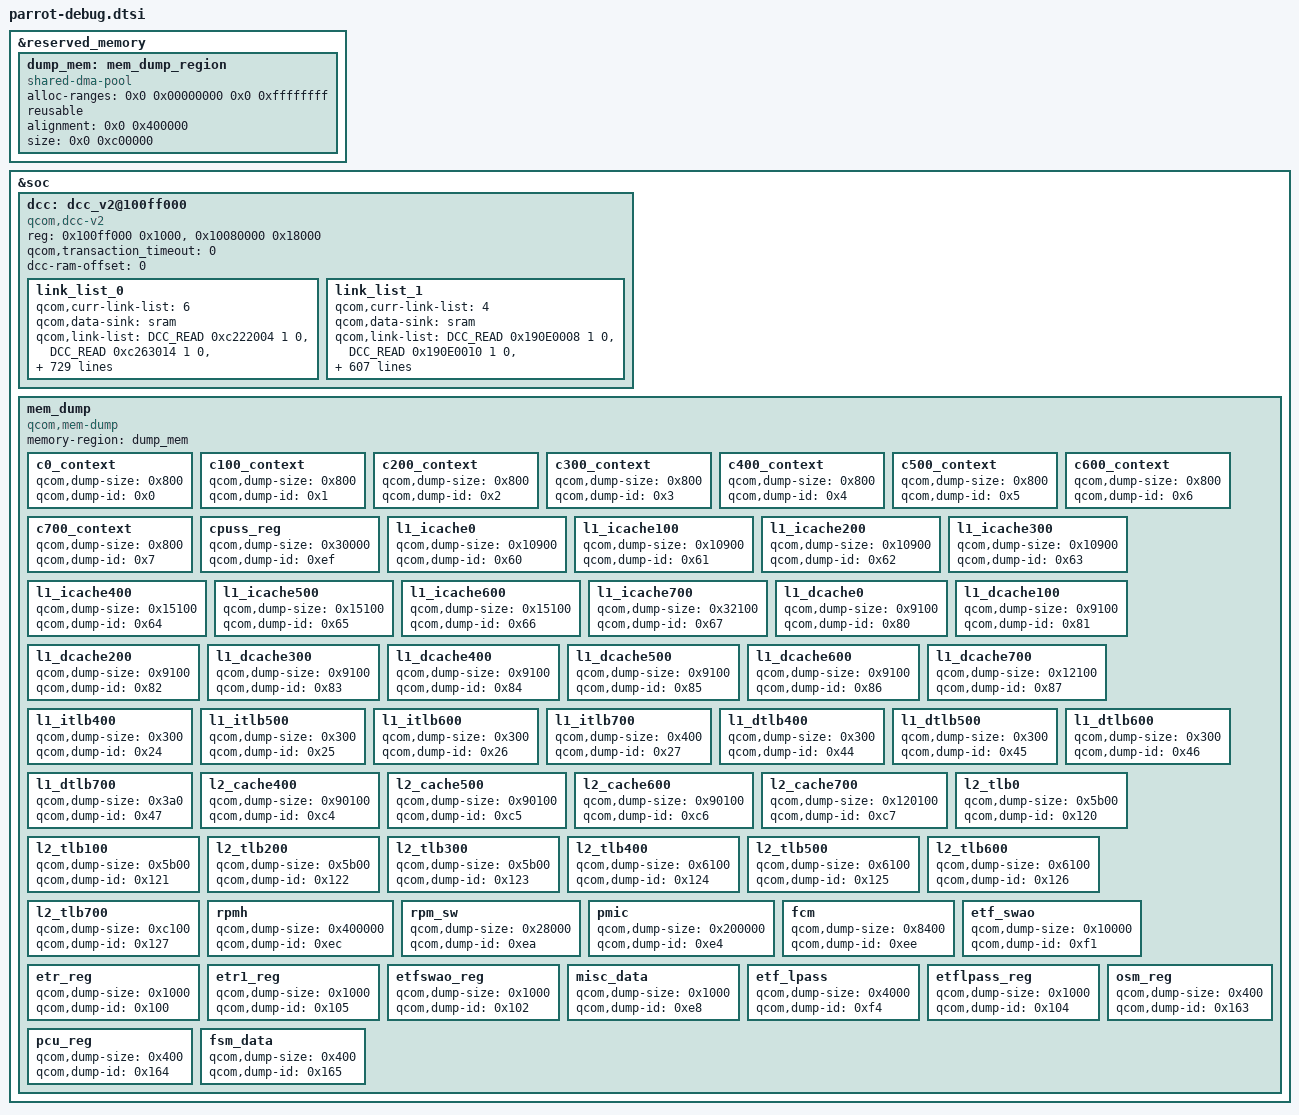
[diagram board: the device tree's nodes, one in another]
#include <dt-bindings/soc/qcom,dcc_v2.h>

&reserved_memory {
	#address-cells = <2>;
	#size-cells = <2>;
	ranges;

	dump_mem: mem_dump_region {
		compatible = "shared-dma-pool";
		alloc-ranges = <0x0 0x00000000 0x0 0xffffffff>;
		reusable;
		alignment = <0x0 0x400000>;
		size = <0x0 0xc00000>;
	};
};

&soc {
	dcc: dcc_v2@100ff000 {
		compatible = "qcom,dcc-v2";
		reg = <0x100ff000 0x1000>,
		      <0x10080000 0x18000>;

		qcom,transaction_timeout = <0>;

		reg-names = "dcc-base", "dcc-ram-base";
		dcc-ram-offset = <0>;

		link_list_0 {
			qcom,curr-link-list = <6>;
			qcom,data-sink = "sram";
			qcom,link-list = <DCC_READ 0xc222004 1 0>,
				<DCC_READ 0xc263014 1 0>,
				<DCC_READ 0xc2630e0 1 0>,
				<DCC_READ 0xc2630ec 1 0>,
				<DCC_READ 0xc2630a0 16 0>,
				<DCC_READ 0xc2630e8 1 0>,
				<DCC_READ 0xc26313c 1 0>,
				<DCC_READ 0xc223004 1 0>,
				<DCC_READ 0xc265014 1 0>,
				<DCC_READ 0xc2650e0 1 0>,
				<DCC_READ 0xc2650ec 1 0>,
				<DCC_READ 0xc2650a0 16 0>,
				<DCC_READ 0xc2650e8 1 0>,
				<DCC_READ 0xc26513c 1 0>,
				<DCC_READ 0x1780005c 1 0>,
				<DCC_READ 0x1781005c 1 0>,
				<DCC_READ 0x1782005c 1 0>,
				<DCC_READ 0x1783005c 1 0>,
				<DCC_READ 0x1784005c 1 0>,
				<DCC_READ 0x1785005c 1 0>,
				<DCC_READ 0x1786005c 1 0>,
				<DCC_READ 0x1787005c 1 0>,
				<DCC_READ 0x1740003c 1 0>,
				<DCC_READ 0x17600238 1 0>,
				<DCC_READ 0x17600240 11 0>,
				<DCC_READ 0x17600404 1 0>,
				<DCC_READ 0x1760041c 2 0>,
				<DCC_READ 0x17600434 1 0>,
				<DCC_READ 0x1760043c 2 0>,
				<DCC_READ 0x17400438 1 0>,
				<DCC_READ 0x17600044 1 0>,
				<DCC_READ 0x17600500 1 0>,
				<DCC_READ 0x17600504 5 0>,
				<DCC_READ 0x17900908 1 0>,
				<DCC_READ 0x17900c18 1 0>,
				<DCC_READ 0x17901908 1 0>,
				<DCC_READ 0x17901c18 1 0>,
				<DCC_READ 0x17b90810 1 0>,
				<DCC_READ 0x17b90814 1 0>,
				<DCC_READ 0x17b90818 1 0>,
				<DCC_READ 0x17b93a84 1 0>,
				<DCC_READ 0x17ba0810 1 0>,
				<DCC_READ 0x17ba0c50 1 0>,
				<DCC_READ 0x17ba0814 1 0>,
				<DCC_READ 0x17ba0c54 1 0>,
				<DCC_READ 0x17ba0818 1 0>,
				<DCC_READ 0x17ba0c58 1 0>,
				<DCC_READ 0x17ba3a84 2 0>,
				<DCC_READ 0x17b93500 40 0>,
				<DCC_READ 0x17ba3500 40 0>,
				<DCC_READ 0x17a80000 16 0>,
				<DCC_READ 0x17a82000 6 0>,
				<DCC_READ 0x17a84000 16 0>,
				<DCC_READ 0x17a86000 6 0>,
				<DCC_READ 0x17a88000 16 0>,
				<DCC_READ 0x17a8a000 6 0>,
				<DCC_READ 0xc201244 1 0>,
				<DCC_READ 0xc202244 1 0>,
				<DCC_READ 0x17b00000 1 0>,
				<DCC_READ 0x17a94030 1 0>,
				<DCC_READ 0x17a9408c 1 0>,
				<DCC_WRITE 0x17a9409c 0x78 0>,
				<DCC_WRITE 0x17a9409c 0x0 0>,
				<DCC_WRITE 0x17a94048 0x1 0>,
				<DCC_WRITE 0x17a94090 0x0 0>,
				<DCC_WRITE 0x17a94090 0x25 0>,
				<DCC_READ 0x17a94098 1 0>,
				<DCC_WRITE 0x17a94048 0x1D 0>,
				<DCC_WRITE 0x17a94090 0x0 0>,
				<DCC_WRITE 0x17a94090 0x25 0>,
				<DCC_READ 0x17a94098 1 0>,
				<DCC_READ 0x17a90030 1 0>,
				<DCC_READ 0x17a9008c 1 0>,
				<DCC_WRITE 0x17a9009c 0x78 0>,
				<DCC_WRITE 0x17a9009c 0x0 0>,
				<DCC_WRITE 0x17a90048 0x1 0>,
				<DCC_WRITE 0x17a90090 0x0 0>,
				<DCC_WRITE 0x17a90090 0x25 0>,
				<DCC_READ 0x17a90098 1 0>,
				<DCC_WRITE 0x17a90048 0x1D 0>,
				<DCC_WRITE 0x17a90090 0x0 0>,
				<DCC_WRITE 0x17a90090 0x25 0>,
				<DCC_READ 0x17a90098 1 0>,
				<DCC_READ 0x17a92030 1 0>,
				<DCC_READ 0x17a9208c 1 0>,
				<DCC_WRITE 0x17a9209c 0x78 0>,
				<DCC_WRITE 0x17a9209c 0x0 0>,
				<DCC_WRITE 0x17a92048 0x1 0>,
				<DCC_WRITE 0x17a92090 0x0 0>,
				<DCC_WRITE 0x17a92090 0x25 0>,
				<DCC_READ 0x17a92098 1 0>,
				<DCC_WRITE 0x17a92048 0x1D 0>,
				<DCC_WRITE 0x17a92090 0x0 0>,
				<DCC_WRITE 0x17a92090 0x25 0>,
				<DCC_READ 0x17a92098 1 0>,
				<DCC_READ 0x221C20A4 1 0>,
				<DCC_READ 0x221c21c4 1 0>,
				<DCC_READ 0x1fc8000 1 0>,
				<DCC_READ 0x17400038 1 0>,
				<DCC_READ 0x17d91020 1 0>,
				<DCC_READ 0x17d92020 1 0>,
				<DCC_READ 0x17d90020 1 0>,
				<DCC_READ 0x17d9134c 1 0>,
				<DCC_READ 0x17d9234c 1 0>,
				<DCC_READ 0x17d9034c 1 0>,
				<DCC_READ 0x17d91300 1 0>,
				<DCC_READ 0x17d92300 1 0>,
				<DCC_READ 0x17d90300 1 0>,
				<DCC_READ 0x17B784A0 12 0>,
				<DCC_READ 0x17B78520 1 0>,
				<DCC_READ 0x17B78588 1 0>,
				<DCC_READ 0x17B78D90 8 0>,
				<DCC_READ 0x17B79010 6 0>,
				<DCC_READ 0x17B79090 6 0>,
				<DCC_READ 0x17B79A90 4 0>,
				<DCC_READ 0x17B70220 2 0>,
				<DCC_READ 0x17B702A0 2 0>,
				<DCC_READ 0x17B704A0 12 0>,
				<DCC_READ 0x17B70520 1 0>,
				<DCC_READ 0x17B70588 1 0>,
				<DCC_READ 0x17B70D90 12 0>,
				<DCC_READ 0x17B71010 10 0>,
				<DCC_READ 0x17B71090 10 0>,
				<DCC_READ 0x17B71A90 8 0>,
				<DCC_READ 0x19100010 1 0>,
				<DCC_READ 0x19100020 1 0>,
				<DCC_READ 0x19100024 1 0>,
				<DCC_READ 0x19100028 1 0>,
				<DCC_READ 0x1910002C 1 0>,
				<DCC_READ 0x19100030 1 0>,
				<DCC_READ 0x19100034 1 0>,
				<DCC_READ 0x19140010 1 0>,
				<DCC_READ 0x19140020 1 0>,
				<DCC_READ 0x19140024 1 0>,
				<DCC_READ 0x19140028 1 0>,
				<DCC_READ 0x1914002C 1 0>,
				<DCC_READ 0x19140030 1 0>,
				<DCC_READ 0x19140034 1 0>,
				<DCC_READ 0x19180010 1 0>,
				<DCC_READ 0x19180020 1 0>,
				<DCC_READ 0x19180024 1 0>,
				<DCC_READ 0x19180028 1 0>,
				<DCC_READ 0x1918002C 1 0>,
				<DCC_READ 0x19180030 1 0>,
				<DCC_READ 0x19180034 1 0>,
				<DCC_READ 0x19180410 1 0>,
				<DCC_READ 0x19180420 1 0>,
				<DCC_READ 0x19180424 1 0>,
				<DCC_READ 0x19180428 1 0>,
				<DCC_READ 0x1918042C 1 0>,
				<DCC_READ 0x19180430 1 0>,
				<DCC_READ 0x19180434 1 0>,
				<DCC_READ 0x19180848 1 0>,
				<DCC_READ 0x19120008 1 0>,
				<DCC_READ 0x1912000C 1 0>,
				<DCC_READ 0x19160008 1 0>,
				<DCC_READ 0x1916000C 1 0>,
				<DCC_READ 0x191B0008 1 0>,
				<DCC_READ 0x191B000C 1 0>,
				<DCC_READ 0x191B0408 1 0>,
				<DCC_READ 0x191B040C 1 0>,
				<DCC_READ 0x191B1080 1 0>,
				<DCC_READ 0x191B1084 1 0>,
				<DCC_READ 0x191B1088 1 0>,
				<DCC_LOOP 0x9 0 0>,
				<DCC_READ 0x191B1090 2 0>,
				<DCC_LOOP 0x1 0 0>,
				<DCC_READ 0x191B1098 1 0>,
				<DCC_READ 0x19161080 1 0>,
				<DCC_READ 0x19161084 1 0>,
				<DCC_READ 0x19161088 1 0>,
				<DCC_LOOP 0x4 0 0>,
				<DCC_READ 0x19161090 2 0>,
				<DCC_LOOP 0x1 0 0>,
				<DCC_READ 0x19161098 1 0>,
				<DCC_READ 0x19121080 1 0>,
				<DCC_READ 0x19121084 1 0>,
				<DCC_READ 0x19121088 1 0>,
				<DCC_LOOP 0x4 0 0>,
				<DCC_READ 0x19121090 2 0>,
				<DCC_LOOP 0x1 0 0>,
				<DCC_READ 0x19121098 1 0>,
				<DCC_READ 0x191B1000 1 0>,
				<DCC_READ 0x191B1004 1 0>,
				<DCC_READ 0x191B1008 1 0>,
				<DCC_LOOP 0x3 0 0>,
				<DCC_READ 0x191B1010 2 0>,
				<DCC_LOOP 0x1 0 0>,
				<DCC_READ 0x191B1018 1 0>,
				<DCC_READ 0x19121000 1 0>,
				<DCC_READ 0x19121004 1 0>,
				<DCC_READ 0x19121008 1 0>,
				<DCC_LOOP 0x2 0 0>,
				<DCC_READ 0x19121010 2 0>,
				<DCC_LOOP 0x1 0 0>,
				<DCC_READ 0x19121018 1 0>,
				<DCC_READ 0x19161000 1 0>,
				<DCC_READ 0x19161004 1 0>,
				<DCC_READ 0x19161008 1 0>,
				<DCC_LOOP 0x2 0 0>,
				<DCC_READ 0x19161010 2 0>,
				<DCC_LOOP 0x1 0 0>,
				<DCC_READ 0x19161018 1 0>,
				<DCC_READ 0x19130010 1 0>,
				<DCC_READ 0x19131010 1 0>,
				<DCC_READ 0x19132010 1 0>,
				<DCC_READ 0x19170010 1 0>,
				<DCC_READ 0x19171010 1 0>,
				<DCC_READ 0x19172010 1 0>,
				<DCC_READ 0x191B3010 1 0>,
				<DCC_READ 0x191B5010 1 0>,
				<DCC_READ 0x191B6010 1 0>,
				<DCC_READ 0x191B7010 1 0>,
				<DCC_READ 0x191B8010 1 0>,
				<DCC_READ 0x191B9010 1 0>,
				<DCC_READ 0x191BA010 1 0>,
				<DCC_READ 0x191BB010 1 0>,
				<DCC_READ 0x191BC010 1 0>,
				<DCC_READ 0x19120010 1 0>,
				<DCC_LOOP 0x4 0 0>,
				<DCC_READ 0x19120030 3 0>,
				<DCC_LOOP 0x1 0 0>,
				<DCC_READ 0x19120008 2 0>,
				<DCC_LOOP 0xC6 0 0>,
				<DCC_READ 0x19120020 2 0>,
				<DCC_LOOP 0x1 0 0>,
				<DCC_READ 0x19160010 1 0>,
				<DCC_LOOP 0x4 0 0>,
				<DCC_READ 0x19160030 3 0>,
				<DCC_LOOP 0x1 0 0>,
				<DCC_READ 0x19160008 2 0>,
				<DCC_LOOP 0xC6 0 0>,
				<DCC_READ 0x19160020 2 0>,
				<DCC_LOOP 0x1 0 0>,
				<DCC_READ 0x191B0010 1 0>,
				<DCC_LOOP 0x4 0 0>,
				<DCC_READ 0x191B0030 3 0>,
				<DCC_LOOP 0x1 0 0>,
				<DCC_READ 0x191B0008 2 0>,
				<DCC_LOOP 0x6A 0 0>,
				<DCC_READ 0x191B0020 2 0>,
				<DCC_LOOP 0x1 0 0>,
				<DCC_READ 0x191B0410 1 0>,
				<DCC_LOOP 0x4 0 0>,
				<DCC_READ 0x191B0430 3 0>,
				<DCC_LOOP 0x1 0 0>,
				<DCC_READ 0x191B0408 2 0>,
				<DCC_LOOP 0x66 0 0>,
				<DCC_READ 0x191B0420 2 0>,
				<DCC_LOOP 0x1 0 0>,
				<DCC_READ 0x19184100 4 0>,
				<DCC_READ 0x19186100 1 0>,
				<DCC_READ 0x3d0201c 1 0>,
				<DCC_READ 0x3d00000 1 0>,
				<DCC_READ 0x3d00008 1 0>,
				<DCC_READ 0x3d00044 1 0>,
				<DCC_READ 0x3d00058 6 0>,
				<DCC_READ 0x3d0007c 20 0>,
				<DCC_READ 0x3d000e0 5 0>,
				<DCC_READ 0x3d00108 1 0>,
				<DCC_READ 0x3d00110 1 0>,
				<DCC_READ 0x3d0011c 1 0>,
				<DCC_READ 0x3d00124 2 0>,
				<DCC_READ 0x3d00140 1 0>,
				<DCC_READ 0x3d00158 1 0>,
				<DCC_READ 0x3d002b4 2 0>,
				<DCC_READ 0x3d002c0 1 0>,
				<DCC_READ 0x3d002d0 1 0>,
				<DCC_READ 0x3d002e0 1 0>,
				<DCC_READ 0x3d002f0 1 0>,
				<DCC_READ 0x3d00300 1 0>,
				<DCC_READ 0x3d00310 1 0>,
				<DCC_READ 0x3d00320 1 0>,
				<DCC_READ 0x3d00330 1 0>,
				<DCC_READ 0x3d00340 1 0>,
				<DCC_READ 0x3d00350 1 0>,
				<DCC_READ 0x3d00360 1 0>,
				<DCC_READ 0x3d00370 1 0>,
				<DCC_READ 0x3d00380 1 0>,
				<DCC_READ 0x3d00390 1 0>,
				<DCC_READ 0x3d003a0 1 0>,
				<DCC_READ 0x3d003b0 1 0>,
				<DCC_READ 0x3d003c0 1 0>,
				<DCC_READ 0x3d003d0 1 0>,
				<DCC_READ 0x3d003e0 1 0>,
				<DCC_READ 0x3d00400 1 0>,
				<DCC_READ 0x3d00410 8 0>,
				<DCC_READ 0x3d0043c 15 0>,
				<DCC_READ 0x3d00800 14 0>,
				<DCC_READ 0x3d00840 4 0>,
				<DCC_READ 0x3d00854 41 0>,
				<DCC_READ 0x3d01444 1 0>,
				<DCC_READ 0x3d014d4 1 0>,
				<DCC_READ 0x3d99800 8 0>,
				<DCC_READ 0x3d99828 1 0>,
				<DCC_READ 0x3d9983c 1 0>,
				<DCC_READ 0x3d998ac 1 0>,
				<DCC_READ 0x18101c 2 0>,
				<DCC_READ 0x3d94000 2 0>,
				<DCC_READ 0x3d95000 4 0>,
				<DCC_READ 0x3d96000 4 0>,
				<DCC_READ 0x3d97000 4 0>,
				<DCC_READ 0x3d98000 4 0>,
				<DCC_READ 0x3d99000 6 0>,
				<DCC_READ 0x3d99050 10 0>,
				<DCC_READ 0x3d990a8 2 0>,
				<DCC_READ 0x3d990b8 3 0>,
				<DCC_READ 0x3d990c8 1 0>,
				<DCC_READ 0x3d99104 8 0>,
				<DCC_READ 0x3d99130 2 0>,
				<DCC_READ 0x3d9913c 7 0>,
				<DCC_READ 0x3d99198 3 0>,
				<DCC_READ 0x3d991e0 3 0>,
				<DCC_READ 0x3d99224 2 0>,
				<DCC_READ 0x3d99280 4 0>,
				<DCC_READ 0x3d992cc 3 0>,
				<DCC_READ 0x3d99314 3 0>,
				<DCC_READ 0x3d99358 3 0>,
				<DCC_READ 0x3d993a0 2 0>,
				<DCC_READ 0x3d993e4 4 0>,
				<DCC_READ 0x3d9942c 2 0>,
				<DCC_READ 0x3d99470 3 0>,
				<DCC_READ 0x3d99500 4 0>,
				<DCC_READ 0x3d99528 39 0>,
				<DCC_READ 0x3d90000 15 0>,
				<DCC_READ 0x3d91000 15 0>,
				<DCC_READ 0x17800010 1 0>,
				<DCC_READ 0x17800024 1 0>,
				<DCC_READ 0x17800038 6 0>,
				<DCC_READ 0x17800058 4 0>,
				<DCC_READ 0x1780006c 1 0>,
				<DCC_READ 0x178000f0 2 0>,
				<DCC_READ 0x17810010 1 0>,
				<DCC_READ 0x17810024 1 0>,
				<DCC_READ 0x17810038 6 0>,
				<DCC_READ 0x17810058 4 0>,
				<DCC_READ 0x1781006c 1 0>,
				<DCC_READ 0x178100f0 2 0>,
				<DCC_READ 0x17820010 1 0>,
				<DCC_READ 0x17820024 1 0>,
				<DCC_READ 0x17820038 6 0>,
				<DCC_READ 0x17820058 4 0>,
				<DCC_READ 0x178200f0 2 0>,
				<DCC_READ 0x17830010 1 0>,
				<DCC_READ 0x17830024 1 0>,
				<DCC_READ 0x17830038 6 0>,
				<DCC_READ 0x17830058 4 0>,
				<DCC_READ 0x178300f0 2 0>,
				<DCC_READ 0x17840010 1 0>,
				<DCC_READ 0x17840024 1 0>,
				<DCC_READ 0x17840038 6 0>,
				<DCC_READ 0x17840058 4 0>,
				<DCC_READ 0x178400f0 2 0>,
				<DCC_READ 0x17850010 1 0>,
				<DCC_READ 0x17850024 1 0>,
				<DCC_READ 0x17850038 6 0>,
				<DCC_READ 0x17850058 4 0>,
				<DCC_READ 0x178500f0 2 0>,
				<DCC_READ 0x17860010 1 0>,
				<DCC_READ 0x17860024 1 0>,
				<DCC_READ 0x17860038 6 0>,
				<DCC_READ 0x17860058 4 0>,
				<DCC_READ 0x178600f0 2 0>,
				<DCC_READ 0x17870010 1 0>,
				<DCC_READ 0x17870024 1 0>,
				<DCC_READ 0x17870038 6 0>,
				<DCC_READ 0x17870058 4 0>,
				<DCC_READ 0x178700f0 2 0>,
				<DCC_READ 0x17880010 1 0>,
				<DCC_READ 0x17880024 1 0>,
				<DCC_READ 0x17880038 6 0>,
				<DCC_READ 0x17880058 4 0>,
				<DCC_READ 0x178800f0 2 0>,
				<DCC_READ 0x1788006c 5 0>,
				<DCC_READ 0x17880084 1 0>,
				<DCC_READ 0x178800f4 5 0>,
				<DCC_READ 0x17880118 9 0>,
				<DCC_READ 0x178801c8 1 0>,
				<DCC_READ 0x1782006c 1 0>,
				<DCC_READ 0x1783006c 1 0>,
				<DCC_READ 0x1784006c 1 0>,
				<DCC_READ 0x1785006c 1 0>,
				<DCC_READ 0x1786006c 1 0>,
				<DCC_READ 0x1787006c 1 0>,
				<DCC_READ 0x17880080 1 0>,
				<DCC_READ 0x17880090 5 0>,
				<DCC_READ 0x178800e0 4 0>,
				<DCC_READ 0x17880108 4 0>,
				<DCC_READ 0x17880140 2 0>,
				<DCC_READ 0x1788019c 2 0>,
				<DCC_READ 0x178801b0 6 0>,
				<DCC_READ 0x178801f0 5 0>,
				<DCC_READ 0x17880258 1 0>,
				<DCC_READ 0x17200104 29 0>,
				<DCC_READ 0x17200204 29 0>,
				<DCC_READ 0x17200384 29 0>,
				<DCC_READ 0x17880250 2 0>,
				<DCC_READ 0x1788025c 1 0>,
				<DCC_READ 0x32302028 1 0>,
				<DCC_READ 0x320a4404 2 0>,
				<DCC_READ 0x323b0404 2 0>,
				<DCC_READ 0x3000304 1 0>,
				<DCC_READ 0x3002028 1 0>,
				<DCC_READ 0x30b0208 3 0>,
				<DCC_READ 0x30b0228 3 0>,
				<DCC_READ 0x30b0248 3 0>,
				<DCC_READ 0x30b0268 3 0>,
				<DCC_READ 0x30b0288 3 0>,
				<DCC_READ 0x30b02a8 3 0>,
				<DCC_READ 0x30b0400 3 0>,
				<DCC_READ 0x3480400 3 0>,
				<DCC_READ 0x320a4400 1 0>,
				<DCC_READ 0x32300304 1 0>,
				<DCC_READ 0x323b0208 3 0>,
				<DCC_READ 0x323b0228 3 0>,
				<DCC_READ 0x323b0248 3 0>,
				<DCC_READ 0x323b0268 3 0>,
				<DCC_READ 0x323b0288 3 0>,
				<DCC_READ 0x323b02a8 3 0>,
				<DCC_READ 0x323b0400 1 0>,
				<DCC_READ 0x17a00010 1 0>,
				<DCC_READ 0x17a10010 1 0>,
				<DCC_READ 0x17a20010 1 0>,
				<DCC_READ 0x17a30010 1 0>,
				<DCC_READ 0x17a00030 1 0>,
				<DCC_READ 0x17a10030 1 0>,
				<DCC_READ 0x17a20030 1 0>,
				<DCC_READ 0x17a20d00 3 0>,
				<DCC_READ 0x17a20d10 3 0>,
				<DCC_READ 0x17a20d30 9 0>,
				<DCC_READ 0x17a30030 1 0>,
				<DCC_READ 0x17a00038 1 0>,
				<DCC_READ 0x17a10038 1 0>,
				<DCC_READ 0x17a20038 1 0>,
				<DCC_READ 0x17a30038 1 0>,
				<DCC_READ 0x17a00040 1 0>,
				<DCC_READ 0x17a10040 1 0>,
				<DCC_READ 0x17a20040 1 0>,
				<DCC_READ 0x17a30040 1 0>,
				<DCC_READ 0x17a00048 1 0>,
				<DCC_READ 0x17a00400 3 0>,
				<DCC_READ 0x17a10400 3 0>,
				<DCC_READ 0x17a20400 3 0>,
				<DCC_READ 0x17a30400 3 0>,
				<DCC_READ 0xB200010 1 0>,
				<DCC_READ 0xB200110 1 0>,
				<DCC_READ 0xB200900 1 0>,
				<DCC_READ 0xB201020 1 0>,
				<DCC_READ 0xB201030 1 0>,
				<DCC_READ 0xB20103C 1 0>,
				<DCC_READ 0xB201200 3 0>,
				<DCC_READ 0xB204510 2 0>,
				<DCC_READ 0xB204520 1 0>,
				<DCC_READ 0x19080024 1 0>,
				<DCC_READ 0x1908002c 1 0>,
				<DCC_READ 0x19080034 1 0>,
				<DCC_READ 0x1908003c 1 0>,
				<DCC_READ 0x19080044 1 0>,
				<DCC_READ 0x1908004c 1 0>,
				<DCC_READ 0x19080058 2 0>,
				<DCC_READ 0x190800c8 1 0>,
				<DCC_READ 0x19080144 1 0>,
				<DCC_READ 0x1908014c 1 0>,
				<DCC_READ 0x19080174 1 0>,
				<DCC_READ 0x1908017c 1 0>,
				<DCC_READ 0x19080184 1 0>,
				<DCC_READ 0x1908018c 1 0>,
				<DCC_READ 0x19080194 1 0>,
				<DCC_READ 0x1908019c 1 0>,
				<DCC_READ 0x190801a4 1 0>,
				<DCC_READ 0x190801ac 3 0>,
				<DCC_READ 0x19091000 1 0>,
				<DCC_READ 0x19092000 1 0>,
				<DCC_READ 0x19093000 1 0>,
				<DCC_READ 0x19093104 1 0>,
				<DCC_READ 0x19094000 1 0>,
				<DCC_READ 0x19094104 1 0>,
				<DCC_READ 0x19095220 1 0>,
				<DCC_READ 0x190a80e4 2 0>,
				<DCC_READ 0x190a80f8 1 0>,
				<DCC_READ 0x190a80f8 5 0>,
				<DCC_READ 0x190a8150 2 0>,
				<DCC_READ 0x190a8164 2 0>,
				<DCC_READ 0x190a8174 4 0>,
				<DCC_READ 0x190a819c 1 0>,
				<DCC_READ 0x190a81cc 1 0>,
				<DCC_READ 0x190A8804 1 0>,
				<DCC_READ 0x190A880C 1 0>,
				<DCC_READ 0x190A8834 1 0>,
				<DCC_READ 0x190A8840 2 0>,
				<DCC_READ 0x190A8854 1 0>,
				<DCC_READ 0x190A8860 3 0>,
				<DCC_READ 0x190A8878 1 0>,
				<DCC_READ 0x190A888C 1 0>,
				<DCC_READ 0x190A9140 10 0>,
				<DCC_READ 0x190A9188 2 0>,
				<DCC_READ 0x190A9198 2 0>,
				<DCC_READ 0x190A91AC 1 0>,
				<DCC_READ 0x190A91B4 1 0>,
				<DCC_READ 0x190A91C4 2 0>,
				<DCC_READ 0x190A91D0 1 0>,
				<DCC_READ 0x190A91E4 1 0>,
				<DCC_READ 0x190AA034 4 0>,
				<DCC_READ 0x190AA04C 1 0>,
				<DCC_READ 0x190AA058 1 0>,
				<DCC_READ 0x190AA064 1 0>,
				<DCC_READ 0x190AA070 1 0>,
				<DCC_READ 0x190a0008 2 0>,
				<DCC_READ 0x190a1008 2 0>,
				<DCC_READ 0x19243400 7 0>,
				<DCC_READ 0x19243420 2 0>,
				<DCC_READ 0x19243430 5 0>,
				<DCC_READ 0x19243460 5 0>,
				<DCC_READ 0x1924390C 1 0>,
				<DCC_READ 0x19243920 1 0>,
				<DCC_READ 0x19250400 2 0>,
				<DCC_READ 0x19250410 3 0>,
				<DCC_READ 0x19250420 2 0>,
				<DCC_READ 0x19250430 1 0>,
				<DCC_READ 0x19250440 1 0>,
				<DCC_READ 0x19250448 1 0>,
				<DCC_READ 0x192504A0 1 0>,
				<DCC_READ 0x192504B0 4 0>,
				<DCC_READ 0x192504D0 2 0>,
				<DCC_READ 0x192504E0 1 0>,
				<DCC_READ 0x19252400 2 0>,
				<DCC_READ 0x19252410 1 0>,
				<DCC_READ 0x19252418 1 0>,
				<DCC_READ 0x19252450 9 0>,
				<DCC_READ 0x19253400 9 0>,
				<DCC_READ 0x19255110 1 0>,
				<DCC_READ 0x19255130 1 0>,
				<DCC_READ 0x19255150 1 0>,
				<DCC_READ 0x19255170 1 0>,
				<DCC_READ 0x19255190 1 0>,
				<DCC_READ 0x19255210 1 0>,
				<DCC_READ 0x19255230 1 0>,
				<DCC_READ 0x192553B0 2 0>,
				<DCC_READ 0x19255840 1 0>,
				<DCC_READ 0x19255920 4 0>,
				<DCC_READ 0x19255B00 8 0>,
				<DCC_READ 0x19255B28 9 0>,
				<DCC_READ 0x19256400 1 0>,
				<DCC_READ 0x19256410 5 0>,
				<DCC_READ 0x19259100 1 0>,
				<DCC_READ 0x19259110 1 0>,
				<DCC_READ 0x19259120 1 0>,
				<DCC_READ 0x19260304 1 0>,
				<DCC_READ 0x19260400 2 0>,
				<DCC_READ 0x19260410 6 0>,
				<DCC_READ 0x19260430 1 0>,
				<DCC_READ 0x19260440 1 0>,
				<DCC_READ 0x19260448 1 0>,
				<DCC_READ 0x192604A0 1 0>,
				<DCC_READ 0x192604B0 4 0>,
				<DCC_READ 0x192604D0 2 0>,
				<DCC_READ 0x192604E0 1 0>,
				<DCC_READ 0x19262400 2 0>,
				<DCC_READ 0x19262410 1 0>,
				<DCC_READ 0x19262418 1 0>,
				<DCC_READ 0x19262420 29 0>,
				<DCC_READ 0x19263400 11 0>,
				<DCC_READ 0x19265110 1 0>,
				<DCC_READ 0x19265130 1 0>,
				<DCC_READ 0x19265150 1 0>,
				<DCC_READ 0x19265170 1 0>,
				<DCC_READ 0x19265190 1 0>,
				<DCC_READ 0x19265210 1 0>,
				<DCC_READ 0x19265230 1 0>,
				<DCC_READ 0x192653B0 2 0>,
				<DCC_READ 0x19265C00 8 0>,
				<DCC_READ 0x19265C28 8 0>,
				<DCC_READ 0x19265C4C 6 0>,
				<DCC_READ 0x19265C70 18 0>,
				<DCC_READ 0x19266400 1 0>,
				<DCC_READ 0x19266410 1 0>,
				<DCC_READ 0x19266418 3 0>,
				<DCC_READ 0x19269100 1 0>,
				<DCC_READ 0x19269110 1 0>,
				<DCC_READ 0x19269120 1 0>,
				<DCC_READ 0x19281814 1 0>,
				<DCC_READ 0x19283814 1 0>,
				<DCC_READ 0x19285014 1 0>,
				<DCC_READ 0x19286C04 1 0>,
				<DCC_READ 0x19286D04 1 0>,
				<DCC_READ 0x1928729C 1 0>,
				<DCC_READ 0x192872A8 1 0>,
				<DCC_READ 0x1928759C 1 0>,
				<DCC_READ 0x192875A8 1 0>,
				<DCC_READ 0x192E0610 4 0>,
				<DCC_READ 0x192E0624 5 0>,
				<DCC_READ 0x192E0640 1 0>,
				<DCC_READ 0x192E0650 4 0>,
				<DCC_READ 0x192E0670 1 0>,
				<DCC_READ 0x192E0680 4 0>,
				<DCC_READ 0x19343400 7 0>,
				<DCC_READ 0x19343420 2 0>,
				<DCC_READ 0x19343430 5 0>,
				<DCC_READ 0x19343460 5 0>,
				<DCC_READ 0x1934390C 1 0>,
				<DCC_READ 0x19343920 1 0>,
				<DCC_READ 0x19350400 2 0>,
				<DCC_READ 0x19350410 3 0>,
				<DCC_READ 0x19350420 2 0>,
				<DCC_READ 0x19350430 1 0>,
				<DCC_READ 0x19350440 1 0>,
				<DCC_READ 0x19350448 1 0>,
				<DCC_READ 0x193504A0 1 0>,
				<DCC_READ 0x193504B0 4 0>,
				<DCC_READ 0x193504D0 2 0>,
				<DCC_READ 0x193504E0 1 0>,
				<DCC_READ 0x19352400 2 0>,
				<DCC_READ 0x19352410 1 0>,
				<DCC_READ 0x19352418 1 0>,
				<DCC_READ 0x19352450 9 0>,
				<DCC_READ 0x19353400 9 0>,
				<DCC_READ 0x19355110 1 0>,
				<DCC_READ 0x19355130 1 0>,
				<DCC_READ 0x19355150 1 0>,
				<DCC_READ 0x19355170 1 0>,
				<DCC_READ 0x19355190 1 0>,
				<DCC_READ 0x19355210 1 0>,
				<DCC_READ 0x19355230 1 0>,
				<DCC_READ 0x193553B0 2 0>,
				<DCC_READ 0x19355840 1 0>,
				<DCC_READ 0x19355920 4 0>,
				<DCC_READ 0x19355B00 8 0>,
				<DCC_READ 0x19355B28 9 0>,
				<DCC_READ 0x19356400 1 0>,
				<DCC_READ 0x19356410 5 0>,
				<DCC_READ 0x19359100 1 0>,
				<DCC_READ 0x19359110 1 0>,
				<DCC_READ 0x19359120 1 0>,
				<DCC_READ 0x19360304 1 0>,
				<DCC_READ 0x19360400 2 0>,
				<DCC_READ 0x19360410 6 0>,
				<DCC_READ 0x19360430 1 0>,
				<DCC_READ 0x19360440 1 0>,
				<DCC_READ 0x19360448 1 0>,
				<DCC_READ 0x193604A0 1 0>,
				<DCC_READ 0x193604B0 4 0>,
				<DCC_READ 0x193604D0 2 0>,
				<DCC_READ 0x193604E0 1 0>,
				<DCC_READ 0x19362400 2 0>,
				<DCC_READ 0x19362410 1 0>,
				<DCC_READ 0x19362418 1 0>,
				<DCC_READ 0x19362420 29 0>,
				<DCC_READ 0x19363400 11 0>,
				<DCC_READ 0x19365110 1 0>,
				<DCC_READ 0x19365130 1 0>,
				<DCC_READ 0x19365150 1 0>,
				<DCC_READ 0x19365170 1 0>,
				<DCC_READ 0x19365190 1 0>,
				<DCC_READ 0x19365210 1 0>,
				<DCC_READ 0x19365230 1 0>,
				<DCC_READ 0x193653B0 2 0>,
				<DCC_READ 0x19365C00 8 0>,
				<DCC_READ 0x19365C28 8 0>,
				<DCC_READ 0x19365C4C 6 0>,
				<DCC_READ 0x19365C70 18 0>,
				<DCC_READ 0x19366400 1 0>,
				<DCC_READ 0x19366410 1 0>,
				<DCC_READ 0x19366418 3 0>,
				<DCC_READ 0x19369100 1 0>,
				<DCC_READ 0x19369110 1 0>,
				<DCC_READ 0x19369120 1 0>,
				<DCC_READ 0x19381814 1 0>,
				<DCC_READ 0x19383814 1 0>,
				<DCC_READ 0x19385014 1 0>,
				<DCC_READ 0x19386C04 1 0>,
				<DCC_READ 0x19386D04 1 0>,
				<DCC_READ 0x1938729C 1 0>,
				<DCC_READ 0x193872A8 1 0>,
				<DCC_READ 0x1938759C 1 0>,
				<DCC_READ 0x193875A8 1 0>,
				<DCC_READ 0x193E0610 4 0>,
				<DCC_READ 0x193E0624 5 0>,
				<DCC_READ 0x193E0640 1 0>,
				<DCC_READ 0x193E0650 4 0>,
				<DCC_READ 0x193E0670 1 0>,
				<DCC_READ 0x193E0680 4 0>,
				<DCC_READ 0x610110 5 0>,
				<DCC_READ 0x1908E008 1 0>,
				<DCC_READ 0x1908E01C 1 0>,
				<DCC_READ 0x1908E030 1 0>,
				<DCC_READ 0x1908E050 1 0>,
				<DCC_READ 0x1908E070 1 0>,
				<DCC_READ 0x1908E948 1 0>,
				<DCC_READ 0x1908F04C 1 0>,
				<DCC_WRITE 0x19030040 0x1 0>,
				<DCC_WRITE 0x1903005c 0x22C000 0>,
				<DCC_READ 0x19030010 1 0>,
				<DCC_WRITE 0x1903005c 0x22C001 0>,
				<DCC_READ 0x19030010 1 0>,
				<DCC_WRITE 0x1903005c 0x22C002 0>,
				<DCC_READ 0x19030010 1 0>,
				<DCC_WRITE 0x1903005c 0x22C003 0>,
				<DCC_READ 0x19030010 1 0>,
				<DCC_WRITE 0x1903005c 0x22C004 0>,
				<DCC_READ 0x19030010 1 0>,
				<DCC_WRITE 0x1903005c 0x22C005 0>,
				<DCC_READ 0x19030010 1 0>,
				<DCC_WRITE 0x1903005c 0x22C006 0>,
				<DCC_READ 0x19030010 1 0>,
				<DCC_WRITE 0x1903005c 0x22C007 0>,
				<DCC_READ 0x19030010 1 0>,
				<DCC_WRITE 0x1903005c 0x22C008 0>,
				<DCC_READ 0x19030010 1 0>,
				<DCC_WRITE 0x1903005c 0x22C009 0>,
				<DCC_READ 0x19030010 1 0>,
				<DCC_WRITE 0x1903005c 0x22C00A 0>,
				<DCC_READ 0x19030010 1 0>,
				<DCC_WRITE 0x1903005c 0x22C00B 0>,
				<DCC_READ 0x19030010 1 0>,
				<DCC_WRITE 0x1903005c 0x22C00C 0>,
				<DCC_READ 0x19030010 1 0>,
				<DCC_WRITE 0x1903005c 0x22C00D 0>,
				<DCC_READ 0x19030010 1 0>,
				<DCC_WRITE 0x1903005c 0x22C00E 0>,
				<DCC_READ 0x19030010 1 0>,
				<DCC_WRITE 0x1903005c 0x22C00F 0>,
				<DCC_READ 0x19030010 1 0>,
				<DCC_WRITE 0x1903005c 0x22C010 0>,
				<DCC_READ 0x19030010 1 0>,
				<DCC_WRITE 0x1903005c 0x22C011 0>,
				<DCC_READ 0x19030010 1 0>,
				<DCC_WRITE 0x1903005c 0x22C012 0>,
				<DCC_READ 0x19030010 1 0>,
				<DCC_WRITE 0x1903005c 0x22C013 0>,
				<DCC_READ 0x19030010 1 0>,
				<DCC_WRITE 0x1903005c 0x22C014 0>,
				<DCC_READ 0x19030010 1 0>,
				<DCC_WRITE 0x1903005c 0x22C015 0>,
				<DCC_READ 0x19030010 1 0>,
				<DCC_WRITE 0x1903005c 0x22C016 0>,
				<DCC_READ 0x19030010 1 0>,
				<DCC_WRITE 0x1903005c 0x22C017 0>,
				<DCC_READ 0x19030010 1 0>,
				<DCC_WRITE 0x1903005c 0x22C018 0>,
				<DCC_READ 0x19030010 1 0>,
				<DCC_WRITE 0x1903005c 0x22C019 0>,
				<DCC_READ 0x19030010 1 0>,
				<DCC_WRITE 0x1903005c 0x22C01A 0>,
				<DCC_READ 0x19030010 1 0>,
				<DCC_WRITE 0x1903005c 0x22C01B 0>,
				<DCC_READ 0x19030010 1 0>,
				<DCC_WRITE 0x1903005c 0x22C01C 0>,
				<DCC_READ 0x19030010 1 0>,
				<DCC_WRITE 0x1903005c 0x22C01D 0>,
				<DCC_READ 0x19030010 1 0>,
				<DCC_WRITE 0x1903005c 0x22C01E 0>,
				<DCC_READ 0x19030010 1 0>,
				<DCC_WRITE 0x1903005c 0x22C01F 0>,
				<DCC_READ 0x19030010 1 0>,
				<DCC_WRITE 0x1903005c 0x22C300 0>,
				<DCC_READ 0x19030010 1 0>,
				<DCC_WRITE 0x1903005c 0x22C341 0>,
				<DCC_READ 0x19030010 1 0>,
				<DCC_READ 0x19030010 1 0>;
		};

		link_list_1 {
			qcom,curr-link-list = <4>;
			qcom,data-sink = "sram";
			qcom,link-list = <DCC_READ 0x190E0008 1 0>,
				<DCC_READ 0x190E0010 1 0>,
				<DCC_READ 0x190E0018 1 0>,
				<DCC_READ 0x190E0020 8 0>,
				<DCC_READ 0x190E0240 1 0>,
				<DCC_READ 0x190E0248 1 0>,
				<DCC_READ 0x190E5008 1 0>,
				<DCC_READ 0x190E5018 1 0>,
				<DCC_LOOP 0x6 0 0>,
				<DCC_READ 0x190E5010 2 0>,
				<DCC_LOOP 0x1 0 0>,
				<DCC_READ 0x3C40008 1 0>,
				<DCC_READ 0x3C40010 1 0>,
				<DCC_READ 0x3C40018 1 0>,
				<DCC_READ 0x3C40020 8 0>,
				<DCC_READ 0x3C4B040 1 0>,
				<DCC_READ 0x3C4B048 1 0>,
				<DCC_READ 0x3C44010 1 0>,
				<DCC_READ 0x3C46010 1 0>,
				<DCC_READ 0x3C41008 1 0>,
				<DCC_READ 0x3C41018 1 0>,
				<DCC_LOOP 0x5 0 0>,
				<DCC_READ 0x3C41010 2 0>,
				<DCC_LOOP 0x1 0 0>,
				<DCC_READ 0x3C4A100 1 0>,
				<DCC_READ 0x1740008 1 0>,
				<DCC_READ 0x1740010 1 0>,
				<DCC_READ 0x1740018 1 0>,
				<DCC_READ 0x1740020 1 0>,
				<DCC_READ 0x1740024 1 0>,
				<DCC_READ 0x1740028 1 0>,
				<DCC_READ 0x174002C 1 0>,
				<DCC_READ 0x1740030 1 0>,
				<DCC_READ 0x1740240 1 0>,
				<DCC_READ 0x1740248 1 0>,
				<DCC_READ 0x1741008 1 0>,
				<DCC_READ 0x1741018 1 0>,
				<DCC_LOOP 0x6 0 0>,
				<DCC_READ 0x1741010 2 0>,
				<DCC_LOOP 0x1 0 0>,
				<DCC_READ 0x1753010 1 0>,
				<DCC_READ 0x1754010 1 0>,
				<DCC_READ 0x1755010 1 0>,
				<DCC_READ 0x1756010 1 0>,
				<DCC_READ 0x1757010 1 0>,
				<DCC_READ 0x1758010 1 0>,
				<DCC_READ 0x1759010 1 0>,
				<DCC_READ 0x1740300 2 0>,
				<DCC_READ 0x1680008 1 0>,
				<DCC_READ 0x1680010 1 0>,
				<DCC_READ 0x1680018 1 0>,
				<DCC_READ 0x1680020 8 0>,
				<DCC_READ 0x1680240 1 0>,
				<DCC_READ 0x1680248 1 0>,
				<DCC_READ 0x1691010 1 0>,
				<DCC_READ 0x1694010 1 0>,
				<DCC_READ 0x1695010 1 0>,
				<DCC_READ 0x1696010 1 0>,
				<DCC_READ 0x1697010 1 0>,
				<DCC_READ 0x1698010 1 0>,
				<DCC_READ 0x1699010 1 0>,
				<DCC_READ 0x1681008 1 0>,
				<DCC_READ 0x1681018 1 0>,
				<DCC_LOOP 0x6 0 0>,
				<DCC_READ 0x1681010 2 0>,
				<DCC_LOOP 0x1 0 0>,
				<DCC_READ 0x16E0000 3 0>,
				<DCC_READ 0x16E0010 1 0>,
				<DCC_READ 0x16E0018 1 0>,
				<DCC_READ 0x16E0020 8 0>,
				<DCC_READ 0x16E0240 1 0>,
				<DCC_READ 0x16E0248 1 0>,
				<DCC_READ 0x16ED010 1 0>,
				<DCC_READ 0x16EE010 1 0>,
				<DCC_READ 0x16EF010 1 0>,
				<DCC_READ 0x16F0010 1 0>,
				<DCC_READ 0x16F2010 1 0>,
				<DCC_READ 0x16C0008 1 0>,
				<DCC_READ 0x16C0010 1 0>,
				<DCC_READ 0x16C0018 1 0>,
				<DCC_READ 0x16C0020 8 0>,
				<DCC_READ 0x16C0240 1 0>,
				<DCC_READ 0x16C0248 1 0>,
				<DCC_READ 0x16C7010 1 0>,
				<DCC_READ 0x1700008 1 0>,
				<DCC_READ 0x1700010 1 0>,
				<DCC_READ 0x1700018 1 0>,
				<DCC_READ 0x1700020 5 0>,
				<DCC_READ 0x1700240 1 0>,
				<DCC_READ 0x1700248 1 0>,
				<DCC_READ 0x170E010 1 0>,
				<DCC_READ 0x170F010 1 0>,
				<DCC_READ 0x1710010 1 0>,
				<DCC_READ 0x1711010 1 0>,
				<DCC_READ 0x1712010 1 0>,
				<DCC_READ 0x1713010 1 0>,
				<DCC_READ 0x1714010 1 0>,
				<DCC_READ 0x1716010 1 0>,
				<DCC_READ 0x16E1008 1 0>,
				<DCC_READ 0x16E1018 1 0>,
				<DCC_LOOP 0x3 0 0>,
				<DCC_READ 0x16E1010 2 0>,
				<DCC_LOOP 0x1 0 0>,
				<DCC_READ 0x16C1008 1 0>,
				<DCC_READ 0x16C1018 1 0>,
				<DCC_LOOP 0x3 0 0>,
				<DCC_READ 0x16C1010 2 0>,
				<DCC_LOOP 0x1 0 0>,
				<DCC_READ 0x1701008 1 0>,
				<DCC_READ 0x1701018 1 0>,
				<DCC_LOOP 0x6 0 0>,
				<DCC_READ 0x1701010 2 0>,
				<DCC_LOOP 0x1 0 0>,
				<DCC_READ 0x1701088 1 0>,
				<DCC_READ 0x1701098 1 0>,
				<DCC_LOOP 0x2 0 0>,
				<DCC_READ 0x1701090 2 0>,
				<DCC_LOOP 0x1 0 0>,
				<DCC_READ 0x1500008 1 0>,
				<DCC_READ 0x1500010 1 0>,
				<DCC_READ 0x1500018 1 0>,
				<DCC_READ 0x1500020 8 0>,
				<DCC_READ 0x1500240 5 0>,
				<DCC_READ 0x1500258 1 0>,
				<DCC_READ 0x1500440 1 0>,
				<DCC_READ 0x1500448 1 0>,
				<DCC_READ 0x1502008 1 0>,
				<DCC_READ 0x1502018 1 0>,
				<DCC_LOOP 0x8 0 0>,
				<DCC_READ 0x1502010 2 0>,
				<DCC_LOOP 0x1 0 0>,
				<DCC_READ 0x1502088 1 0>,
				<DCC_READ 0x1502098 1 0>,
				<DCC_LOOP 0x3 0 0>,
				<DCC_READ 0x1502090 2 0>,
				<DCC_LOOP 0x1 0 0>,
				<DCC_READ 0x1502108 1 0>,
				<DCC_READ 0x1502118 1 0>,
				<DCC_LOOP 0x2 0 0>,
				<DCC_READ 0x1502110 2 0>,
				<DCC_LOOP 0x1 0 0>,
				<DCC_READ 0x1502188 1 0>,
				<DCC_READ 0x1502198 1 0>,
				<DCC_LOOP 0x2 0 0>,
				<DCC_READ 0x1502190 2 0>,
				<DCC_LOOP 0x1 0 0>,
				<DCC_READ 0x1502208 1 0>,
				<DCC_READ 0x1502218 1 0>,
				<DCC_LOOP 0x2 0 0>,
				<DCC_READ 0x1502210 2 0>,
				<DCC_LOOP 0x1 0 0>,
				<DCC_READ 0x1502288 1 0>,
				<DCC_READ 0x1502298 1 0>,
				<DCC_LOOP 0x2 0 0>,
				<DCC_READ 0x1502290 2 0>,
				<DCC_LOOP 0x1 0 0>,
				<DCC_READ 0x1510008 1 0>,
				<DCC_READ 0x1510010 1 0>,
				<DCC_READ 0x1510018 1 0>,
				<DCC_READ 0x1510020 8 0>,
				<DCC_READ 0x1510240 1 0>,
				<DCC_READ 0x1510248 1 0>,
				<DCC_READ 0x1510440 1 0>,
				<DCC_READ 0x1510448 1 0>,
				<DCC_READ 0x1512008 1 0>,
				<DCC_READ 0x1512018 1 0>,
				<DCC_LOOP 0xb 0 0>,
				<DCC_READ 0x1512010 2 0>,
				<DCC_LOOP 0x1 0 0>,
				<DCC_READ 0x1512088 1 0>,
				<DCC_READ 0x1512098 1 0>,
				<DCC_LOOP 0x2 0 0>,
				<DCC_READ 0x1512090 2 0>,
				<DCC_LOOP 0x1 0 0>,
				<DCC_READ 0x1506100 1 0>,
				<DCC_READ 0x1515100 1 0>,
				<DCC_READ 0x1513100 1 0>,
				<DCC_READ 0xb281024 1 0>,
				<DCC_READ 0xbde1034 1 0>,
				<DCC_READ 0xb201020 2 0>,
				<DCC_READ 0xb211020 2 0>,
				<DCC_READ 0xb221020 2 0>,
				<DCC_READ 0xb231020 2 0>,
				<DCC_READ 0xb204520 1 0>,
				<DCC_READ 0xc230000 6 0>,
				<DCC_READ 0x17d80100 200 0>,
				<DCC_READ 0x17D9001C 1 0>,
				<DCC_READ 0x17D900DC 1 0>,
				<DCC_READ 0x17D900E8 1 0>,
				<DCC_READ 0x17D90320 1 0>,
				<DCC_READ 0x17D9101C 1 0>,
				<DCC_READ 0x17D910DC 1 0>,
				<DCC_READ 0x17D910E8 1 0>,
				<DCC_READ 0x17D91320 1 0>,
				<DCC_READ 0x17D9201C 1 0>,
				<DCC_READ 0x17D920DC 1 0>,
				<DCC_READ 0x17D920E8 1 0>,
				<DCC_READ 0x17D92320 1 0>,
				<DCC_READ 0x17d80000 3 0>,
				<DCC_READ 0x17d80010 2 0>,
				<DCC_READ 0x17d90000 4 0>,
				<DCC_READ 0x17d90014 2 0>,
				<DCC_READ 0x17d90024 22 0>,
				<DCC_READ 0x17d90080 5 0>,
				<DCC_READ 0x17d900b0 1 0>,
				<DCC_READ 0x17d900b8 2 0>,
				<DCC_READ 0x17d900d0 3 0>,
				<DCC_READ 0x17d900e0 2 0>,
				<DCC_READ 0x17d900ec 2 0>,
				<DCC_READ 0x17d90100 40 0>,
				<DCC_READ 0x17d90200 40 0>,
				<DCC_READ 0x17d90304 4 0>,
				<DCC_READ 0x17d90350 30 0>,
				<DCC_READ 0x17d903e0 2 0>,
				<DCC_READ 0x17d90404 1 0>,
				<DCC_READ 0x17d91000 4 0>,
				<DCC_READ 0x17d91014 2 0>,
				<DCC_READ 0x17d91024 22 0>,
				<DCC_READ 0x17d91080 8 0>,
				<DCC_READ 0x17d910b0 1 0>,
				<DCC_READ 0x17d910b8 2 0>,
				<DCC_READ 0x17d910d0 3 0>,
				<DCC_READ 0x17d910e0 2 0>,
				<DCC_READ 0x17d910ec 2 0>,
				<DCC_READ 0x17d91100 40 0>,
				<DCC_READ 0x17d91200 40 0>,
				<DCC_READ 0x17d91304 4 0>,
				<DCC_READ 0x17d91324 3 0>,
				<DCC_READ 0x17d91350 34 0>,
				<DCC_READ 0x17d913e0 5 0>,
				<DCC_READ 0x17d91404 1 0>,
				<DCC_READ 0x17d92000 4 0>,
				<DCC_READ 0x17d92014 2 0>,
				<DCC_READ 0x17d92024 22 0>,
				<DCC_READ 0x17d92080 7 0>,
				<DCC_READ 0x17d920b0 1 0>,
				<DCC_READ 0x17d920b8 2 0>,
				<DCC_READ 0x17d920d0 3 0>,
				<DCC_READ 0x17d920e0 2 0>,
				<DCC_READ 0x17d920ec 2 0>,
				<DCC_READ 0x17d92100 40 0>,
				<DCC_READ 0x17d92200 40 0>,
				<DCC_READ 0x17d92304 4 0>,
				<DCC_READ 0x17d92324 2 0>,
				<DCC_READ 0x17d92350 33 0>,
				<DCC_READ 0x17d923e0 4 0>,
				<DCC_READ 0x17d92404 1 0>,
				<DCC_READ 0x17d98000 8 0>,
				<DCC_READ 0x17d98020 2 0>,
				<DCC_READ 0x17220000 1 0>,
				<DCC_READ 0x17220008 1 0>,
				<DCC_READ 0x17220010 1 0>,
				<DCC_READ 0x17220018 1 0>,
				<DCC_READ 0x17220020 1 0>,
				<DCC_READ 0x17220028 1 0>,
				<DCC_READ 0x17220040 1 0>,
				<DCC_READ 0x17220048 1 0>,
				<DCC_READ 0x17220050 1 0>,
				<DCC_READ 0x17220060 1 0>,
				<DCC_READ 0x17220068 1 0>,
				<DCC_READ 0x17220080 1 0>,
				<DCC_READ 0x17220088 1 0>,
				<DCC_READ 0x17220090 1 0>,
				<DCC_READ 0x172200A0 1 0>,
				<DCC_READ 0x172200A8 1 0>,
				<DCC_READ 0x172200C0 1 0>,
				<DCC_READ 0x172200C8 1 0>,
				<DCC_READ 0x172200D0 1 0>,
				<DCC_READ 0x172200E0 1 0>,
				<DCC_READ 0x172200E8 1 0>,
				<DCC_READ 0x17220100 1 0>,
				<DCC_READ 0x17220108 1 0>,
				<DCC_READ 0x17220110 1 0>,
				<DCC_READ 0x17220120 1 0>,
				<DCC_READ 0x17220128 1 0>,
				<DCC_READ 0x17220140 1 0>,
				<DCC_READ 0x17220148 1 0>,
				<DCC_READ 0x17220150 1 0>,
				<DCC_READ 0x17220160 1 0>,
				<DCC_READ 0x17220168 1 0>,
				<DCC_READ 0x17220180 1 0>,
				<DCC_READ 0x17220188 1 0>,
				<DCC_READ 0x17220190 1 0>,
				<DCC_READ 0x172201A0 1 0>,
				<DCC_READ 0x172201A8 1 0>,
				<DCC_READ 0x172201C0 1 0>,
				<DCC_READ 0x172201C8 1 0>,
				<DCC_READ 0x172201D0 1 0>,
				<DCC_READ 0x172201E0 1 0>,
				<DCC_READ 0x172201E8 1 0>,
				<DCC_READ 0x17220200 1 0>,
				<DCC_READ 0x17220208 1 0>,
				<DCC_READ 0x17220210 1 0>,
				<DCC_READ 0x17220220 1 0>,
				<DCC_READ 0x17220228 1 0>,
				<DCC_READ 0x17220240 1 0>,
				<DCC_READ 0x17220248 1 0>,
				<DCC_READ 0x17220250 1 0>,
				<DCC_READ 0x17220260 1 0>,
				<DCC_READ 0x17220268 1 0>,
				<DCC_READ 0x17220280 1 0>,
				<DCC_READ 0x17220288 1 0>,
				<DCC_READ 0x17220290 1 0>,
				<DCC_READ 0x172202A0 1 0>,
				<DCC_READ 0x172202A8 1 0>,
				<DCC_READ 0x172202C0 1 0>,
				<DCC_READ 0x172202C8 1 0>,
				<DCC_READ 0x172202D0 1 0>,
				<DCC_READ 0x172202E0 1 0>,
				<DCC_READ 0x172202E8 1 0>,
				<DCC_READ 0x17220300 1 0>,
				<DCC_READ 0x17220308 1 0>,
				<DCC_READ 0x17220310 1 0>,
				<DCC_READ 0x17220320 1 0>,
				<DCC_READ 0x17220328 1 0>,
				<DCC_READ 0x17220340 1 0>,
				<DCC_READ 0x17220348 1 0>,
				<DCC_READ 0x17220350 1 0>,
				<DCC_READ 0x17220360 1 0>,
				<DCC_READ 0x17220368 1 0>,
				<DCC_READ 0x1722E000 1 0>,
				<DCC_READ 0x1722E800 1 0>,
				<DCC_READ 0x1722E808 1 0>,
				<DCC_READ 0x1722FFBC 1 0>,
				<DCC_READ 0x1722FFC8 1 0>,
				<DCC_READ 0x1722FFD0 12 0>,
				<DCC_READ 0xEC80010 1 0>,
				<DCC_READ 0xEC81000 1 0>,
				<DCC_READ 0xEC81010 16 0>,
				<DCC_READ 0xEC81050 16 0>,
				<DCC_READ 0xEC81090 16 0>,
				<DCC_READ 0xEC810D0 16 0>,
				<DCC_READ 0x32310220 3 0>,
				<DCC_READ 0x323102A0 3 0>,
				<DCC_READ 0x323104A0 6 0>,
				<DCC_READ 0x32310520 1 0>,
				<DCC_READ 0x32310588 1 0>,
				<DCC_READ 0x32310D90 8 0>,
				<DCC_READ 0x32311010 6 0>,
				<DCC_READ 0x32311090 6 0>,
				<DCC_READ 0x32311A90 3 0>,
				<DCC_READ 0x4080304 1 0>,
				<DCC_READ 0x4082028 1 0>,
				<DCC_READ 0x4130208 3 0>,
				<DCC_READ 0x4130228 3 0>,
				<DCC_READ 0x4130248 3 0>,
				<DCC_READ 0x4130268 3 0>,
				<DCC_READ 0x4130288 3 0>,
				<DCC_READ 0x41302a8 3 0>,
				<DCC_READ 0x4130400 3 0>,
				<DCC_READ 0x4200400 3 0>,
				<DCC_READ 0x8a00304 1 0>,
				<DCC_READ 0x8a02028 1 0>,
				<DCC_READ 0x8ab0208 3 0>,
				<DCC_READ 0x8ab0228 3 0>,
				<DCC_READ 0x8ab0248 3 0>,
				<DCC_READ 0x8ab0268 3 0>,
				<DCC_READ 0x8ab0288 3 0>,
				<DCC_READ 0x8ab02a8 3 0>,
				<DCC_READ 0x8ab0400 3 0>,
				<DCC_READ 0x8b00400 3 0>,
				<DCC_READ 0x12015C 2 0>,
				<DCC_READ 0x120464 2 0>,
				<DCC_READ 0x12C15C 2 0>,
				<DCC_READ 0x12C464 2 0>,
				<DCC_READ 0x188040 1 0>,
				<DCC_READ 0x1A0884 1 0>,
				<DCC_READ 0x1A915C 2 0>,
				<DCC_READ 0x1A9464 2 0>,
				<DCC_READ 0x120018 4 0>,
				<DCC_READ 0x12002c 3 0>,
				<DCC_READ 0x12015C 2 0>,
				<DCC_READ 0x120464 2 0>,
				<DCC_READ 0x121004 1 0>,
				<DCC_READ 0x12100c 2 0>,
				<DCC_READ 0x124004 1 0>,
				<DCC_READ 0x12400c 2 0>,
				<DCC_READ 0x125004 1 0>,
				<DCC_READ 0x125010 1 0>,
				<DCC_READ 0x127004 3 0>,
				<DCC_READ 0x127140 1 0>,
				<DCC_READ 0x127274 1 0>,
				<DCC_READ 0x1273a8 1 0>,
				<DCC_READ 0x1274dc 1 0>,
				<DCC_READ 0x127610 1 0>,
				<DCC_READ 0x127744 1 0>,
				<DCC_READ 0x128004 3 0>,
				<DCC_READ 0x128140 1 0>,
				<DCC_READ 0x128274 1 0>,
				<DCC_READ 0x1283a8 1 0>,
				<DCC_READ 0x1284dc 1 0>,
				<DCC_READ 0x128610 1 0>,
				<DCC_READ 0x128748 1 0>,
				<DCC_READ 0x12C15C 2 0>,
				<DCC_READ 0x12C464 2 0>,
				<DCC_READ 0x12a004 1 0>,
				<DCC_READ 0x12b004 1 0>,
				<DCC_READ 0x12b00c 1 0>,
				<DCC_READ 0x12c018 1 0>,
				<DCC_READ 0x12c020 1 0>,
				<DCC_READ 0x12c028 1 0>,
				<DCC_READ 0x12c030 5 0>,
				<DCC_READ 0x12c174 1 0>,
				<DCC_READ 0x12c2a8 1 0>,
				<DCC_READ 0x12c2c8 7 0>,
				<DCC_READ 0x12d004 2 0>,
				<DCC_READ 0x12f004 3 0>,
				<DCC_READ 0x12f014 18 0>,
				<DCC_READ 0x12f77c 7 0>,
				<DCC_READ 0x130004 2 0>,
				<DCC_READ 0x131000 2 0>,
				<DCC_READ 0x132004 1 0>,
				<DCC_READ 0x133000 1 0>,
				<DCC_READ 0x13300c 1 0>,
				<DCC_READ 0x133140 1 0>,
				<DCC_READ 0x13314c 1 0>,
				<DCC_READ 0x134004 1 0>,
				<DCC_READ 0x135004 2 0>,
				<DCC_READ 0x136004 7 0>,
				<DCC_READ 0x137004 3 0>,
				<DCC_READ 0x137014 1 0>,
				<DCC_READ 0x142004 3 0>,
				<DCC_READ 0x142014 2 0>,
				<DCC_READ 0x143004 3 0>,
				<DCC_READ 0x144004 6 0>,
				<DCC_READ 0x146004 2 0>,
				<DCC_READ 0x147004 2 0>,
				<DCC_READ 0x148004 1 0>,
				<DCC_READ 0x149018 1 0>,
				<DCC_READ 0x149020 2 0>,
				<DCC_READ 0x14905c 3 0>,
				<DCC_READ 0x149084 3 0>,
				<DCC_READ 0x14a004 2 0>,
				<DCC_READ 0x14b004 3 0>,
				<DCC_READ 0x14b028 2 0>,
				<DCC_READ 0x14c004 3 0>,
				<DCC_READ 0x14d000 1 0>,
				<DCC_READ 0x150004 7 0>,
				<DCC_READ 0x151004 1 0>,
				<DCC_READ 0x15100c 2 0>,
				<DCC_READ 0x153000 6 0>,
				<DCC_READ 0x154004 8 0>,
				<DCC_READ 0x155000 5 0>,
				<DCC_READ 0x155144 1 0>,
				<DCC_READ 0x156004 4 0>,
				<DCC_READ 0x15602c 2 0>,
				<DCC_READ 0x157000 6 0>,
				<DCC_READ 0x15701c 2 0>,
				<DCC_READ 0x158000 4 0>,
				<DCC_READ 0x158174 3 0>,
				<DCC_READ 0x159004 1 0>,
				<DCC_READ 0x15e004 2 0>,
				<DCC_READ 0x172008 2 0>,
				<DCC_READ 0x172018 1 0>,
				<DCC_READ 0x174000 1 0>,
				<DCC_READ 0x175000 1 0>,
				<DCC_READ 0x176000 1 0>,
				<DCC_READ 0x17a004 1 0>,
				<DCC_READ 0x17b018 3 0>,
				<DCC_READ 0x17b028 1 0>,
				<DCC_READ 0x17b030 2 0>,
				<DCC_READ 0x17b03c 1 0>,
				<DCC_READ 0x17b044 1 0>,
				<DCC_READ 0x17b08c 3 0>,
				<DCC_READ 0x181004 6 0>,
				<DCC_READ 0x181154 1 0>,
				<DCC_READ 0x184004 24 0>,
				<DCC_READ 0x184794 1 0>,
				<DCC_READ 0x18479c 1 0>,
				<DCC_READ 0x1847a4 1 0>,
				<DCC_READ 0x1847ac 2 0>,
				<DCC_READ 0x1847b8 10 0>,
				<DCC_READ 0x186004 6 0>,
				<DCC_READ 0x187018 1 0>,
				<DCC_READ 0x187020 3 0>,
				<DCC_READ 0x187064 1 0>,
				<DCC_READ 0x18706c 1 0>,
				<DCC_READ 0x1870a4 1 0>,
				<DCC_READ 0x1870c0 1 0>,
				<DCC_READ 0x1870d4 1 0>,
				<DCC_READ 0x188040 1 0>,
				<DCC_READ 0x18a004 6 0>,
				<DCC_READ 0x18a04c 5 0>,
				<DCC_READ 0x192004 15 0>,
				<DCC_READ 0x1923f0 1 0>,
				<DCC_READ 0x1923f8 3 0>,
				<DCC_READ 0x193004 2 0>,
				<DCC_READ 0x193140 1 0>,
				<DCC_READ 0x194004 1 0>,
				<DCC_READ 0x198004 1 0>,
				<DCC_READ 0x199018 1 0>,
				<DCC_READ 0x199020 1 0>,
				<DCC_READ 0x199028 2 0>,
				<DCC_READ 0x199164 3 0>,
				<DCC_READ 0x19a000 9 0>,
				<DCC_READ 0x19a28c 3 0>,
				<DCC_READ 0x19b004 3 0>,
				<DCC_READ 0x1A0884 1 0>,
				<DCC_READ 0x1A915C 2 0>,
				<DCC_READ 0x1A9464 2 0>,
				<DCC_READ 0x1a0004 1 0>,
				<DCC_READ 0x1a000c 1 0>,
				<DCC_READ 0x1a0014 1 0>,
				<DCC_READ 0x1a8004 1 0>,
				<DCC_READ 0x1a9014 1 0>,
				<DCC_READ 0x1a901c 1 0>,
				<DCC_READ 0x1b0134 2 0>,
				<DCC_READ 0x1b0154 9 0>,
				<DCC_READ 0x1b017c 1 0>,
				<DCC_READ 0x1b2004 7 0>,
				<DCC_READ 0x1b3004 2 0>,
				<DCC_READ 0x1b3028 1 0>,
				<DCC_READ 0x1b3048 1 0>,
				<DCC_READ 0x1b4004 1 0>,
				<DCC_READ 0x100000 2 0>,
				<DCC_READ 0x101000 2 0>,
				<DCC_READ 0x102000 2 0>,
				<DCC_READ 0x103000 2 0>,
				<DCC_READ 0x104000 2 0>,
				<DCC_READ 0x105000 2 0>,
				<DCC_READ 0x106000 2 0>,
				<DCC_READ 0x107000 2 0>,
				<DCC_READ 0x108000 2 0>,
				<DCC_READ 0x109000 2 0>,
				<DCC_READ 0x10a000 2 0>,
				<DCC_READ 0x116100 1 0>,
				<DCC_READ 0x120004 2 0>,
				<DCC_READ 0x127028 1 0>,
				<DCC_READ 0x12715c 1 0>,
				<DCC_READ 0x127290 1 0>,
				<DCC_READ 0x1273c4 1 0>,
				<DCC_READ 0x1274f8 1 0>,
				<DCC_READ 0x12762c 1 0>,
				<DCC_READ 0x128028 1 0>,
				<DCC_READ 0x12815c 1 0>,
				<DCC_READ 0x128290 1 0>,
				<DCC_READ 0x1283c4 1 0>,
				<DCC_READ 0x1284f8 1 0>,
				<DCC_READ 0x12862c 1 0>,
				<DCC_READ 0x12c004 2 0>,
				<DCC_READ 0x12c058 1 0>,
				<DCC_READ 0x133028 1 0>,
				<DCC_READ 0x146020 1 0>,
				<DCC_READ 0x149004 2 0>,
				<DCC_READ 0x151028 1 0>,
				<DCC_READ 0x154164 1 0>,
				<DCC_READ 0x155028 1 0>,
				<DCC_READ 0x16301c 1 0>,
				<DCC_READ 0x163024 1 0>,
				<DCC_READ 0x16302c 1 0>,
				<DCC_READ 0x163034 1 0>,
				<DCC_READ 0x165000 1 0>,
				<DCC_READ 0x165008 1 0>,
				<DCC_READ 0x165010 1 0>,
				<DCC_READ 0x165018 1 0>,
				<DCC_READ 0x166000 1 0>,
				<DCC_READ 0x166008 1 0>,
				<DCC_READ 0x166010 1 0>,
				<DCC_READ 0x166018 1 0>,
				<DCC_READ 0x167000 1 0>,
				<DCC_READ 0x167008 1 0>,
				<DCC_READ 0x167010 1 0>,
				<DCC_READ 0x167018 1 0>,
				<DCC_READ 0x16a000 1 0>,
				<DCC_READ 0x16a008 1 0>,
				<DCC_READ 0x16a010 1 0>,
				<DCC_READ 0x16a018 1 0>,
				<DCC_READ 0x16b000 1 0>,
				<DCC_READ 0x16b008 1 0>,
				<DCC_READ 0x16b010 1 0>,
				<DCC_READ 0x16b018 1 0>,
				<DCC_READ 0x17901c 1 0>,
				<DCC_READ 0x179024 1 0>,
				<DCC_READ 0x17902c 1 0>,
				<DCC_READ 0x179034 1 0>,
				<DCC_READ 0x17b004 2 0>,
				<DCC_READ 0x184078 1 0>,
				<DCC_READ 0x186038 1 0>,
				<DCC_READ 0x187004 2 0>,
				<DCC_READ 0x193024 1 0>,
				<DCC_READ 0x199004 2 0>,
				<DCC_READ 0x199044 1 0>,
				<DCC_READ 0x1a9000 2 0>,
				<DCC_READ 0x1b101c 1 0>,
				<DCC_READ 0x1b1024 1 0>,
				<DCC_READ 0x1b102c 1 0>,
				<DCC_READ 0x1b1034 1 0>,
				<DCC_READ 0xc2a0000 2 0>,
				<DCC_READ 0xc2a1000 2 0>,
				<DCC_READ 0xc2a900c 1 0>,
				<DCC_READ 0xc2a901c 1 0>,
				<DCC_READ 0xc2a9024 1 0>,
				<DCC_READ 0x1dc7000 3 0>,
				<DCC_READ 0x1dc8000 3 0>,
				<DCC_READ 0x1dc9000 3 0>,
				<DCC_READ 0x1dca000 3 0>,
				<DCC_READ 0x320C0008 1 0>,
				<DCC_READ 0x320C0010 1 0>,
				<DCC_READ 0x320C0018 1 0>,
				<DCC_READ 0x320C0020 8 0>,
				<DCC_READ 0x320C1000 2 0>,
				<DCC_READ 0x320C1040 1 0>,
				<DCC_READ 0x320C1048 1 0>,
				<DCC_READ 0x320C1080 1 0>,
				<DCC_READ 0x320C1088 1 0>,
				<DCC_READ 0x320C1090 1 0>,
				<DCC_READ 0x320C1100 4 0>,
				<DCC_READ 0x320C4000 3 0>,
				<DCC_LOOP 0x4 0 0>,
				<DCC_READ 0x320C4010 2 0>,
				<DCC_LOOP 0x1 0 0>,
				<DCC_READ 0x320C4018 1 0>,
				<DCC_READ 0x320C4100 3 0>,
				<DCC_READ 0x320C4110 1 0>,
				<DCC_READ 0x320C4118 1 0>,
				<DCC_READ 0x320C4800 3 0>,
				<DCC_READ 0x320C4840 1 0>,
				<DCC_READ 0x320C5000 3 0>,
				<DCC_READ 0x320C5010 1 0>,
				<DCC_READ 0x320C5018 1 0>,
				<DCC_READ 0x320C5020 1 0>,
				<DCC_READ 0x320C5028 1 0>,
				<DCC_READ 0x320C5030 1 0>,
				<DCC_READ 0x320C5038 1 0>,
				<DCC_READ 0x320C5040 1 0>,
				<DCC_READ 0x320C5048 1 0>,
				<DCC_READ 0x320C5100 1 0>,
				<DCC_READ 0x320C5140 1 0>,
				<DCC_READ 0x320C5180 1 0>,
				<DCC_READ 0x320C51C0 1 0>,
				<DCC_READ 0x320C5200 1 0>,
				<DCC_READ 0x320C5240 1 0>,
				<DCC_READ 0x320C5280 1 0>,
				<DCC_READ 0x320C52C0 1 0>,
				<DCC_READ 0x320C5300 1 0>,
				<DCC_READ 0x320C5340 1 0>,
				<DCC_READ 0x320C5380 1 0>,
				<DCC_READ 0x320C53C0 1 0>,
				<DCC_READ 0x320C5400 1 0>,
				<DCC_READ 0x320C5440 1 0>,
				<DCC_READ 0x320C5480 1 0>,
				<DCC_READ 0x320C54C0 1 0>,
				<DCC_READ 0x320C5540 1 0>;
		};
	};

	mem_dump {
		compatible = "qcom,mem-dump";
		memory-region = <&dump_mem>;

		c0_context {
			qcom,dump-size = <0x800>;
			qcom,dump-id = <0x0>;
		};

		c100_context {
			qcom,dump-size = <0x800>;
			qcom,dump-id = <0x1>;
		};

		c200_context {
			qcom,dump-size = <0x800>;
			qcom,dump-id = <0x2>;
		};

		c300_context {
			qcom,dump-size = <0x800>;
			qcom,dump-id = <0x3>;
		};

		c400_context {
			qcom,dump-size = <0x800>;
			qcom,dump-id = <0x4>;
		};

		c500_context {
			qcom,dump-size = <0x800>;
			qcom,dump-id = <0x5>;
		};

		c600_context {
			qcom,dump-size = <0x800>;
			qcom,dump-id = <0x6>;
		};

		c700_context {
			qcom,dump-size = <0x800>;
			qcom,dump-id = <0x7>;
		};

		cpuss_reg {
			qcom,dump-size = <0x30000>;
			qcom,dump-id = <0xef>;
		};

		l1_icache0 {
			qcom,dump-size = <0x10900>;
			qcom,dump-id = <0x60>;
		};

		l1_icache100 {
			qcom,dump-size = <0x10900>;
			qcom,dump-id = <0x61>;
		};

		l1_icache200 {
			qcom,dump-size = <0x10900>;
			qcom,dump-id = <0x62>;
		};

		l1_icache300 {
			qcom,dump-size = <0x10900>;
			qcom,dump-id = <0x63>;
		};

		l1_icache400 {
			qcom,dump-size = <0x15100>;
			qcom,dump-id = <0x64>;
		};

		l1_icache500 {
			qcom,dump-size = <0x15100>;
			qcom,dump-id = <0x65>;
		};

		l1_icache600 {
			qcom,dump-size = <0x15100>;
			qcom,dump-id = <0x66>;
		};

		l1_icache700 {
			qcom,dump-size = <0x32100>;
			qcom,dump-id = <0x67>;
		};

		l1_dcache0 {
			qcom,dump-size = <0x9100>;
			qcom,dump-id = <0x80>;
		};

		l1_dcache100 {
			qcom,dump-size = <0x9100>;
			qcom,dump-id = <0x81>;
		};

		l1_dcache200 {
			qcom,dump-size = <0x9100>;
			qcom,dump-id = <0x82>;
		};

		l1_dcache300 {
			qcom,dump-size = <0x9100>;
			qcom,dump-id = <0x83>;
		};

		l1_dcache400 {
			qcom,dump-size = <0x9100>;
			qcom,dump-id = <0x84>;
		};

		l1_dcache500 {
			qcom,dump-size = <0x9100>;
			qcom,dump-id = <0x85>;
		};

		l1_dcache600 {
			qcom,dump-size = <0x9100>;
			qcom,dump-id = <0x86>;
		};

		l1_dcache700 {
			qcom,dump-size = <0x12100>;
			qcom,dump-id = <0x87>;
		};

		l1_itlb400 {
			qcom,dump-size = <0x300>;
			qcom,dump-id = <0x24>;
		};

		l1_itlb500 {
			qcom,dump-size = <0x300>;
			qcom,dump-id = <0x25>;
		};

		l1_itlb600 {
			qcom,dump-size = <0x300>;
			qcom,dump-id = <0x26>;
		};

		l1_itlb700 {
			qcom,dump-size = <0x400>;
			qcom,dump-id = <0x27>;
		};

		l1_dtlb400 {
			qcom,dump-size = <0x300>;
			qcom,dump-id = <0x44>;
		};

		l1_dtlb500 {
			qcom,dump-size = <0x300>;
			qcom,dump-id = <0x45>;
		};

		l1_dtlb600 {
			qcom,dump-size = <0x300>;
			qcom,dump-id = <0x46>;
		};

		l1_dtlb700 {
			qcom,dump-size = <0x3a0>;
			qcom,dump-id = <0x47>;
		};

		l2_cache400 {
			qcom,dump-size = <0x90100>;
			qcom,dump-id = <0xc4>;
		};

		l2_cache500 {
			qcom,dump-size = <0x90100>;
			qcom,dump-id = <0xc5>;
		};

		l2_cache600 {
			qcom,dump-size = <0x90100>;
			qcom,dump-id = <0xc6>;
		};

		l2_cache700 {
			qcom,dump-size = <0x120100>;
			qcom,dump-id = <0xc7>;
		};

		l2_tlb0 {
			qcom,dump-size = <0x5b00>;
			qcom,dump-id = <0x120>;
		};

		l2_tlb100 {
			qcom,dump-size = <0x5b00>;
			qcom,dump-id = <0x121>;
		};

		l2_tlb200 {
			qcom,dump-size = <0x5b00>;
			qcom,dump-id = <0x122>;
		};

		l2_tlb300 {
			qcom,dump-size = <0x5b00>;
			qcom,dump-id = <0x123>;
		};

		l2_tlb400 {
			qcom,dump-size = <0x6100>;
			qcom,dump-id = <0x124>;
		};

		l2_tlb500 {
			qcom,dump-size = <0x6100>;
			qcom,dump-id = <0x125>;
		};

		l2_tlb600 {
			qcom,dump-size = <0x6100>;
			qcom,dump-id = <0x126>;
		};

		l2_tlb700 {
			qcom,dump-size = <0xc100>;
			qcom,dump-id = <0x127>;
		};

		rpmh {
			qcom,dump-size = <0x400000>;
			qcom,dump-id = <0xec>;
		};

		rpm_sw {
			qcom,dump-size = <0x28000>;
			qcom,dump-id = <0xea>;
		};

		pmic {
			qcom,dump-size = <0x200000>;
			qcom,dump-id = <0xe4>;
		};

		fcm {
			qcom,dump-size = <0x8400>;
			qcom,dump-id = <0xee>;
		};

		etf_swao {
			qcom,dump-size = <0x10000>;
			qcom,dump-id = <0xf1>;
		};

		etr_reg {
			qcom,dump-size = <0x1000>;
			qcom,dump-id = <0x100>;
		};

		etr1_reg {
			qcom,dump-size = <0x1000>;
			qcom,dump-id = <0x105>;
		};

		etfswao_reg {
			qcom,dump-size = <0x1000>;
			qcom,dump-id = <0x102>;
		};

		misc_data {
			qcom,dump-size = <0x1000>;
			qcom,dump-id = <0xe8>;
		};

		etf_lpass {
			qcom,dump-size = <0x4000>;
			qcom,dump-id = <0xf4>;
		};

		etflpass_reg {
			qcom,dump-size = <0x1000>;
			qcom,dump-id = <0x104>;
		};

		osm_reg {
			qcom,dump-size = <0x400>;
			qcom,dump-id = <0x163>;
		};

		pcu_reg {
			qcom,dump-size = <0x400>;
			qcom,dump-id = <0x164>;
		};

		fsm_data {
			qcom,dump-size = <0x400>;
			qcom,dump-id = <0x165>;
		};
	};
};
